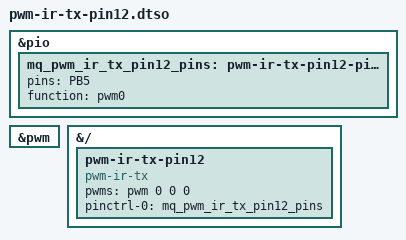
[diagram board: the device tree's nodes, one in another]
// SPDX-License-Identifier: (GPL-2.0+ OR MIT)
// Mangue OS header overlay pwm-ir-tx-pin12 — GENERATED by tools/gen_overlays.py,
// edit overlays/header_table.py instead.
//
// pin port  role
//  12 PB5   pwm0
// device: /dev/lircN (transmit)

/dts-v1/;
/plugin/;

#include <dt-bindings/gpio/gpio.h>
#include <dt-bindings/interrupt-controller/irq.h>
#include <dt-bindings/input/linux-event-codes.h>

&pio {
	mq_pwm_ir_tx_pin12_pins: pwm-ir-tx-pin12-pins {
		pins = "PB5";
		function = "pwm0";
	};
};

&pwm {
	status = "okay";
};

&{/} {
	pwm-ir-tx-pin12 {
		compatible = "pwm-ir-tx";
		pwms = <&pwm 0 0 0>;
		pinctrl-names = "default";
		pinctrl-0 = <&mq_pwm_ir_tx_pin12_pins>;
	};
};
